AUTOSAR XML (schema 4-2-2)
package /STELLANTIS/EPT/ASWCs
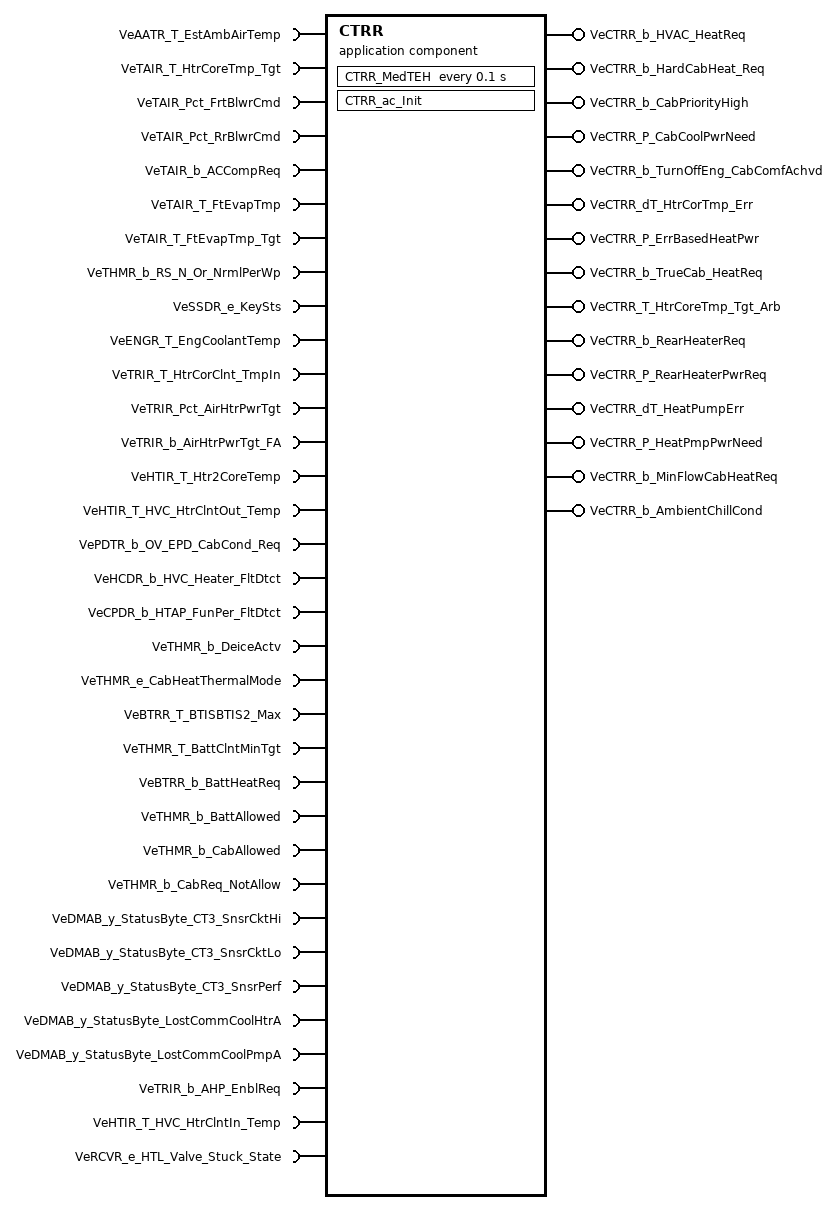
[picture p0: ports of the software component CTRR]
  application sw component type CTRR
    34 x require port:
      VeAATR_T_EstAmbAirTemp: variation-point={short-label=vpVeAATR_T_EstAmbAirTemp, sw-syscond=1}, nonqueued-receiver-com-spec{data-element=Value, init-value=0}, required-interface=VeAATR_T_EstAmbAirTemp
      VeTAIR_T_HtrCoreTmp_Tgt: variation-point={short-label=vpVeTAIR_T_HtrCoreTmp_Tgt, sw-syscond=1}, nonqueued-receiver-com-spec{data-element=Value, init-value=0}, required-interface=VeTAIR_T_HtrCoreTmp_Tgt
      VeTAIR_Pct_FrtBlwrCmd: variation-point={short-label=vpVeTAIR_Pct_FrtBlwrCmd, sw-syscond=1}, nonqueued-receiver-com-spec{data-element=Value, init-value=0}, required-interface=VeTAIR_Pct_FrtBlwrCmd
      VeTAIR_Pct_RrBlwrCmd: variation-point={short-label=vpVeTAIR_Pct_RrBlwrCmd, sw-syscond=1}, nonqueued-receiver-com-spec{data-element=Value, init-value=0}, required-interface=VeTAIR_Pct_RrBlwrCmd
      VeTAIR_b_ACCompReq: variation-point={short-label=vpVeTAIR_b_ACCompReq, sw-syscond=1}, nonqueued-receiver-com-spec{data-element=Value, init-value=0}, required-interface=VeTAIR_b_ACCompReq
      VeTAIR_T_FtEvapTmp: variation-point={short-label=vpVeTAIR_T_FtEvapTmp, sw-syscond=1}, nonqueued-receiver-com-spec{data-element=Value, init-value=0}, required-interface=VeTAIR_T_FtEvapTmp
      VeTAIR_T_FtEvapTmp_Tgt: variation-point={short-label=vpVeTAIR_T_FtEvapTmp_Tgt, sw-syscond=1}, nonqueued-receiver-com-spec{data-element=Value, init-value=0}, required-interface=VeTAIR_T_FtEvapTmp_Tgt
      VeTHMR_b_RS_N_Or_NrmlPerWp: variation-point={short-label=vpVeTHMR_b_RS_N_Or_NrmlPerWp, sw-syscond=1}, nonqueued-receiver-com-spec{data-element=Value, init-value=0}, required-interface=VeTHMR_b_RS_N_Or_NrmlPerWp
      VeSSDR_e_KeySts: variation-point={short-label=vpVeSSDR_e_KeySts, sw-syscond=1}, nonqueued-receiver-com-spec{data-element=Value, init-value=CeSSDR_e_KeyOff}, required-interface=VeSSDR_e_KeySts
      VeENGR_T_EngCoolantTemp: variation-point={short-label=vpVeENGR_T_EngCoolantTemp, sw-syscond=1}, nonqueued-receiver-com-spec{data-element=Value, init-value=0}, required-interface=VeENGR_T_EngCoolantTemp
      VeTRIR_T_HtrCorClnt_TmpIn: variation-point={short-label=vpVeTRIR_T_HtrCorClnt_TmpIn, sw-syscond=1}, nonqueued-receiver-com-spec{data-element=Value, init-value=0}, required-interface=VeTRIR_T_HtrCorClnt_TmpIn
      VeTRIR_Pct_AirHtrPwrTgt: variation-point={short-label=vpVeTRIR_Pct_AirHtrPwrTgt, sw-syscond=1}, nonqueued-receiver-com-spec{data-element=Value, init-value=0}, required-interface=VeTRIR_Pct_AirHtrPwrTgt
      VeTRIR_b_AirHtrPwrTgt_FA: variation-point={short-label=vpVeTRIR_b_AirHtrPwrTgt_FA, sw-syscond=1}, nonqueued-receiver-com-spec{data-element=Value, init-value=0}, required-interface=VeTRIR_b_AirHtrPwrTgt_FA
      VeHTIR_T_Htr2CoreTemp: variation-point={short-label=vpVeHTIR_T_Htr2CoreTemp, sw-syscond=1}, nonqueued-receiver-com-spec{data-element=Value, init-value=0}, required-interface=VeHTIR_T_Htr2CoreTemp
      VeHTIR_T_HVC_HtrClntOut_Temp: variation-point={short-label=vpVeHTIR_T_HVC_HtrClntOut_Temp, sw-syscond=1}, nonqueued-receiver-com-spec{data-element=Value, init-value=0}, required-interface=VeHTIR_T_HVC_HtrClntOut_Temp
      VePDTR_b_OV_EPD_CabCond_Req: variation-point={short-label=vpVePDTR_b_OV_EPD_CabCond_Req, sw-syscond=1}, nonqueued-receiver-com-spec{data-element=Value, init-value=0}, required-interface=VePDTR_b_OV_EPD_CabCond_Req
      VeHCDR_b_HVC_Heater_FltDtct: variation-point={short-label=vpVeHCDR_b_HVC_Heater_FltDtct, sw-syscond=1}, nonqueued-receiver-com-spec{data-element=Value, init-value=0}, required-interface=VeHCDR_b_HVC_Heater_FltDtct
      VeCPDR_b_HTAP_FunPer_FltDtct: variation-point={short-label=vpVeCPDR_b_HTAP_FunPer_FltDtct, sw-syscond=1}, nonqueued-receiver-com-spec{data-element=Value, init-value=0}, required-interface=VeCPDR_b_HTAP_FunPer_FltDtct
      VeTHMR_b_DeiceActv: variation-point={short-label=vpVeTHMR_b_DeiceActv, sw-syscond=1}, nonqueued-receiver-com-spec{data-element=Value, init-value=0}, required-interface=VeTHMR_b_DeiceActv
      VeTHMR_e_CabHeatThermalMode: variation-point={short-label=vpVeTHMR_e_CabHeatThermalMode, sw-syscond=1}, nonqueued-receiver-com-spec{data-element=Value, init-value=CeTHMR_e_NoActvHeat}, required-interface=VeTHMR_e_CabHeatThermalMode
      VeBTRR_T_BTISBTIS2_Max: variation-point={short-label=vpVeBTRR_T_BTISBTIS2_Max, sw-syscond=1}, nonqueued-receiver-com-spec{data-element=Value, init-value=0}, required-interface=VeBTRR_T_BTISBTIS2_Max
      VeTHMR_T_BattClntMinTgt: variation-point={short-label=vpVeTHMR_T_BattClntMinTgt, sw-syscond=1}, nonqueued-receiver-com-spec{data-element=Value, init-value=0}, required-interface=VeTHMR_T_BattClntMinTgt
      VeBTRR_b_BattHeatReq: variation-point={short-label=vpVeBTRR_b_BattHeatReq, sw-syscond=1}, nonqueued-receiver-com-spec{data-element=Value, init-value=0}, required-interface=VeBTRR_b_BattHeatReq
      VeTHMR_b_BattAllowed: variation-point={short-label=vpVeTHMR_b_BattAllowed, sw-syscond=1}, nonqueued-receiver-com-spec{data-element=Value, init-value=0}, required-interface=VeTHMR_b_BattAllowed
      VeTHMR_b_CabAllowed: variation-point={short-label=vpVeTHMR_b_CabAllowed, sw-syscond=1}, nonqueued-receiver-com-spec{data-element=Value, init-value=0}, required-interface=VeTHMR_b_CabAllowed
      VeTHMR_b_CabReq_NotAllow: variation-point={short-label=vpVeTHMR_b_CabReq_NotAllow, sw-syscond=1}, nonqueued-receiver-com-spec{data-element=Value, init-value=0}, required-interface=VeTHMR_b_CabReq_NotAllow
      VeDMAB_y_StatusByte_CT3_SnsrCktHi: variation-point={short-label=vpVeDMAB_y_StatusByte_CT3_SnsrCktHi, sw-syscond=1}, nonqueued-receiver-com-spec{data-element=Value, init-value=0}, required-interface=VeDMAB_y_StatusByte_CT3_SnsrCktHi
      VeDMAB_y_StatusByte_CT3_SnsrCktLo: variation-point={short-label=vpVeDMAB_y_StatusByte_CT3_SnsrCktLo, sw-syscond=1}, nonqueued-receiver-com-spec{data-element=Value, init-value=0}, required-interface=VeDMAB_y_StatusByte_CT3_SnsrCktLo
      VeDMAB_y_StatusByte_CT3_SnsrPerf: variation-point={short-label=vpVeDMAB_y_StatusByte_CT3_SnsrPerf, sw-syscond=1}, nonqueued-receiver-com-spec{data-element=Value, init-value=0}, required-interface=VeDMAB_y_StatusByte_CT3_SnsrPerf
      VeDMAB_y_StatusByte_LostCommCoolHtrA: variation-point={short-label=vpVeDMAB_y_StatusByte_LostCommCoolHtrA, sw-syscond=1}, nonqueued-receiver-com-spec{data-element=Value, init-value=0}, required-interface=VeDMAB_y_StatusByte_LostCommCoolHtrA
      VeDMAB_y_StatusByte_LostCommCoolPmpA: variation-point={short-label=vpVeDMAB_y_StatusByte_LostCommCoolPmpA, sw-syscond=1}, nonqueued-receiver-com-spec{data-element=Value, init-value=0}, required-interface=VeDMAB_y_StatusByte_LostCommCoolPmpA
      VeTRIR_b_AHP_EnblReq: variation-point={short-label=vpVeTRIR_b_AHP_EnblReq, sw-syscond=1}, nonqueued-receiver-com-spec{data-element=Value, init-value=0}, required-interface=VeTRIR_b_AHP_EnblReq
      VeHTIR_T_HVC_HtrClntIn_Temp: variation-point={short-label=vpVeHTIR_T_HVC_HtrClntIn_Temp, sw-syscond=1}, nonqueued-receiver-com-spec{data-element=Value, init-value=0}, required-interface=VeHTIR_T_HVC_HtrClntIn_Temp
      VeRCVR_e_HTL_Valve_Stuck_State: variation-point={short-label=vpVeRCVR_e_HTL_Valve_Stuck_State, sw-syscond=1}, nonqueued-receiver-com-spec{data-element=Value, init-value=CeRCVR_e_Closed}, required-interface=VeRCVR_e_HTL_Valve_Stuck_State
    15 x provide port, all with nonqueued-sender-com-spec{data-element=Value, init-value=0}:
      VeCTRR_b_HVAC_HeatReq: variation-point={short-label=vpVeCTRR_b_HVAC_HeatReq, sw-syscond=1}, provided-interface=VeCTRR_b_HVAC_HeatReq
      VeCTRR_b_HardCabHeat_Req: variation-point={short-label=vpVeCTRR_b_HardCabHeat_Req, sw-syscond=1}, provided-interface=VeCTRR_b_HardCabHeat_Req
      VeCTRR_b_CabPriorityHigh: variation-point={short-label=vpVeCTRR_b_CabPriorityHigh, sw-syscond=1}, provided-interface=VeCTRR_b_CabPriorityHigh
      VeCTRR_P_CabCoolPwrNeed: variation-point={short-label=vpVeCTRR_P_CabCoolPwrNeed, sw-syscond=1}, provided-interface=VeCTRR_P_CabCoolPwrNeed
      VeCTRR_b_TurnOffEng_CabComfAchvd: variation-point={short-label=vpVeCTRR_b_TurnOffEng_CabComfAchvd, sw-syscond=1}, provided-interface=VeCTRR_b_TurnOffEng_CabComfAchvd
      VeCTRR_dT_HtrCorTmp_Err: variation-point={short-label=vpVeCTRR_dT_HtrCorTmp_Err, sw-syscond=1}, provided-interface=VeCTRR_dT_HtrCorTmp_Err
      VeCTRR_P_ErrBasedHeatPwr: variation-point={short-label=vpVeCTRR_P_ErrBasedHeatPwr, sw-syscond=1}, provided-interface=VeCTRR_P_ErrBasedHeatPwr
      VeCTRR_b_TrueCab_HeatReq: variation-point={short-label=vpVeCTRR_b_TrueCab_HeatReq, sw-syscond=1}, provided-interface=VeCTRR_b_TrueCab_HeatReq
      VeCTRR_T_HtrCoreTmp_Tgt_Arb: variation-point={short-label=vpVeCTRR_T_HtrCoreTmp_Tgt_Arb, sw-syscond=1}, provided-interface=VeCTRR_T_HtrCoreTmp_Tgt_Arb
      VeCTRR_b_RearHeaterReq: variation-point={short-label=vpVeCTRR_b_RearHeaterReq, sw-syscond=1}, provided-interface=VeCTRR_b_RearHeaterReq
      VeCTRR_P_RearHeaterPwrReq: variation-point={short-label=vpVeCTRR_P_RearHeaterPwrReq, sw-syscond=1}, provided-interface=VeCTRR_P_RearHeaterPwrReq
      VeCTRR_dT_HeatPumpErr: variation-point={short-label=vpVeCTRR_dT_HeatPumpErr, sw-syscond=1}, provided-interface=VeCTRR_dT_HeatPumpErr
      VeCTRR_P_HeatPmpPwrNeed: variation-point={short-label=vpVeCTRR_P_HeatPmpPwrNeed, sw-syscond=1}, provided-interface=VeCTRR_P_HeatPmpPwrNeed
      VeCTRR_b_MinFlowCabHeatReq: variation-point={short-label=vpVeCTRR_b_MinFlowCabHeatReq, sw-syscond=1}, provided-interface=VeCTRR_b_MinFlowCabHeatReq
      VeCTRR_b_AmbientChillCond: variation-point={short-label=vpVeCTRR_b_AmbientChillCond, sw-syscond=1}, provided-interface=VeCTRR_b_AmbientChillCond
    behavior IB_CTRR: data-type-mapping=msADTtoIDTMapping, handle-termination-and-restart=NO-SUPPORT
      timing event Event_MedTEH: start-on-event=CTRR_MedTEH, period=0.1
      init event Event_CTRR_ac_Init: start-on-event=CTRR_ac_Init
      runnable CTRR_ac_Init
      runnable CTRR_MedTEH: variation-point={short-label=vpCTRR_MedTEH, sw-syscond=1}
        data-receive-point-by-arguments:
          34 x access:
            IN_VeAATR_T_EstAmbAirTemp_Value: accessed-variable=VeAATR_T_EstAmbAirTemp.Value, variation-point={short-label=vpIN_VeAATR_T_EstAmbAirTemp_Value, sw-syscond=1}
            IN_VeBTRR_T_BTISBTIS2_Max_Value: accessed-variable=VeBTRR_T_BTISBTIS2_Max.Value, variation-point={short-label=vpIN_VeBTRR_T_BTISBTIS2_Max_Value, sw-syscond=1}
            IN_VeBTRR_b_BattHeatReq_Value: accessed-variable=VeBTRR_b_BattHeatReq.Value, variation-point={short-label=vpIN_VeBTRR_b_BattHeatReq_Value, sw-syscond=1}
            IN_VeCPDR_b_HTAP_FunPer_FltDtct_Value: accessed-variable=VeCPDR_b_HTAP_FunPer_FltDtct.Value, variation-point={short-label=vpIN_VeCPDR_b_HTAP_FunPer_FltDtct_Value, sw-syscond=1}
            IN_VeDMAB_y_StatusByte_CT3_SnsrCktHi_Value: accessed-variable=VeDMAB_y_StatusByte_CT3_SnsrCktHi.Value, variation-point={short-label=vpIN_VeDMAB_y_StatusByte_CT3_SnsrCktHi_Value, sw-syscond=1}
            IN_VeDMAB_y_StatusByte_CT3_SnsrCktLo_Value: accessed-variable=VeDMAB_y_StatusByte_CT3_SnsrCktLo.Value, variation-point={short-label=vpIN_VeDMAB_y_StatusByte_CT3_SnsrCktLo_Value, sw-syscond=1}
            IN_VeDMAB_y_StatusByte_CT3_SnsrPerf_Value: accessed-variable=VeDMAB_y_StatusByte_CT3_SnsrPerf.Value, variation-point={short-label=vpIN_VeDMAB_y_StatusByte_CT3_SnsrPerf_Value, sw-syscond=1}
            IN_VeDMAB_y_StatusByte_LostCommCoolHtrA_Value: accessed-variable=VeDMAB_y_StatusByte_LostCommCoolHtrA.Value, variation-point={short-label=vpIN_VeDMAB_y_StatusByte_LostCommCoolHtrA_Value, sw-syscond=1}
            IN_VeDMAB_y_StatusByte_LostCommCoolPmpA_Value: accessed-variable=VeDMAB_y_StatusByte_LostCommCoolPmpA.Value, variation-point={short-label=vpIN_VeDMAB_y_StatusByte_LostCommCoolPmpA_Value, sw-syscond=1}
            IN_VeENGR_T_EngCoolantTemp_Value: accessed-variable=VeENGR_T_EngCoolantTemp.Value, variation-point={short-label=vpIN_VeENGR_T_EngCoolantTemp_Value, sw-syscond=1}
            IN_VeHCDR_b_HVC_Heater_FltDtct_Value: accessed-variable=VeHCDR_b_HVC_Heater_FltDtct.Value, variation-point={short-label=vpIN_VeHCDR_b_HVC_Heater_FltDtct_Value, sw-syscond=1}
            IN_VeHTIR_T_HVC_HtrClntIn_Temp_Value: accessed-variable=VeHTIR_T_HVC_HtrClntIn_Temp.Value, variation-point={short-label=vpIN_VeHTIR_T_HVC_HtrClntIn_Temp_Value, sw-syscond=1}
            IN_VeHTIR_T_HVC_HtrClntOut_Temp_Value: accessed-variable=VeHTIR_T_HVC_HtrClntOut_Temp.Value, variation-point={short-label=vpIN_VeHTIR_T_HVC_HtrClntOut_Temp_Value, sw-syscond=1}
            IN_VeHTIR_T_Htr2CoreTemp_Value: accessed-variable=VeHTIR_T_Htr2CoreTemp.Value, variation-point={short-label=vpIN_VeHTIR_T_Htr2CoreTemp_Value, sw-syscond=1}
            IN_VePDTR_b_OV_EPD_CabCond_Req_Value: accessed-variable=VePDTR_b_OV_EPD_CabCond_Req.Value, variation-point={short-label=vpIN_VePDTR_b_OV_EPD_CabCond_Req_Value, sw-syscond=1}
            IN_VeRCVR_e_HTL_Valve_Stuck_State_Value: accessed-variable=VeRCVR_e_HTL_Valve_Stuck_State.Value, variation-point={short-label=vpIN_VeRCVR_e_HTL_Valve_Stuck_State_Value, sw-syscond=1}
            IN_VeSSDR_e_KeySts_Value: accessed-variable=VeSSDR_e_KeySts.Value, variation-point={short-label=vpIN_VeSSDR_e_KeySts_Value, sw-syscond=1}
            IN_VeTAIR_Pct_FrtBlwrCmd_Value: accessed-variable=VeTAIR_Pct_FrtBlwrCmd.Value, variation-point={short-label=vpIN_VeTAIR_Pct_FrtBlwrCmd_Value, sw-syscond=1}
            IN_VeTAIR_Pct_RrBlwrCmd_Value: accessed-variable=VeTAIR_Pct_RrBlwrCmd.Value, variation-point={short-label=vpIN_VeTAIR_Pct_RrBlwrCmd_Value, sw-syscond=1}
            IN_VeTAIR_T_FtEvapTmp_Value: accessed-variable=VeTAIR_T_FtEvapTmp.Value, variation-point={short-label=vpIN_VeTAIR_T_FtEvapTmp_Value, sw-syscond=1}
            IN_VeTAIR_T_FtEvapTmp_Tgt_Value: accessed-variable=VeTAIR_T_FtEvapTmp_Tgt.Value, variation-point={short-label=vpIN_VeTAIR_T_FtEvapTmp_Tgt_Value, sw-syscond=1}
            IN_VeTAIR_T_HtrCoreTmp_Tgt_Value: accessed-variable=VeTAIR_T_HtrCoreTmp_Tgt.Value, variation-point={short-label=vpIN_VeTAIR_T_HtrCoreTmp_Tgt_Value, sw-syscond=1}
            IN_VeTAIR_b_ACCompReq_Value: accessed-variable=VeTAIR_b_ACCompReq.Value, variation-point={short-label=vpIN_VeTAIR_b_ACCompReq_Value, sw-syscond=1}
            IN_VeTHMR_T_BattClntMinTgt_Value: accessed-variable=VeTHMR_T_BattClntMinTgt.Value, variation-point={short-label=vpIN_VeTHMR_T_BattClntMinTgt_Value, sw-syscond=1}
            IN_VeTHMR_b_BattAllowed_Value: accessed-variable=VeTHMR_b_BattAllowed.Value, variation-point={short-label=vpIN_VeTHMR_b_BattAllowed_Value, sw-syscond=1}
            IN_VeTHMR_b_CabAllowed_Value: accessed-variable=VeTHMR_b_CabAllowed.Value, variation-point={short-label=vpIN_VeTHMR_b_CabAllowed_Value, sw-syscond=1}
            IN_VeTHMR_b_CabReq_NotAllow_Value: accessed-variable=VeTHMR_b_CabReq_NotAllow.Value, variation-point={short-label=vpIN_VeTHMR_b_CabReq_NotAllow_Value, sw-syscond=1}
            IN_VeTHMR_b_DeiceActv_Value: accessed-variable=VeTHMR_b_DeiceActv.Value, variation-point={short-label=vpIN_VeTHMR_b_DeiceActv_Value, sw-syscond=1}
            IN_VeTHMR_b_RS_N_Or_NrmlPerWp_Value: accessed-variable=VeTHMR_b_RS_N_Or_NrmlPerWp.Value, variation-point={short-label=vpIN_VeTHMR_b_RS_N_Or_NrmlPerWp_Value, sw-syscond=1}
            IN_VeTHMR_e_CabHeatThermalMode_Value: accessed-variable=VeTHMR_e_CabHeatThermalMode.Value, variation-point={short-label=vpIN_VeTHMR_e_CabHeatThermalMode_Value, sw-syscond=1}
            IN_VeTRIR_Pct_AirHtrPwrTgt_Value: accessed-variable=VeTRIR_Pct_AirHtrPwrTgt.Value, variation-point={short-label=vpIN_VeTRIR_Pct_AirHtrPwrTgt_Value, sw-syscond=1}
            IN_VeTRIR_T_HtrCorClnt_TmpIn_Value: accessed-variable=VeTRIR_T_HtrCorClnt_TmpIn.Value, variation-point={short-label=vpIN_VeTRIR_T_HtrCorClnt_TmpIn_Value, sw-syscond=1}
            IN_VeTRIR_b_AHP_EnblReq_Value: accessed-variable=VeTRIR_b_AHP_EnblReq.Value, variation-point={short-label=vpIN_VeTRIR_b_AHP_EnblReq_Value, sw-syscond=1}
            IN_VeTRIR_b_AirHtrPwrTgt_FA_Value: accessed-variable=VeTRIR_b_AirHtrPwrTgt_FA.Value, variation-point={short-label=vpIN_VeTRIR_b_AirHtrPwrTgt_FA_Value, sw-syscond=1}
        data-send-points:
          15 x access:
            OUT_VeCTRR_b_HVAC_HeatReq_Value: accessed-variable=VeCTRR_b_HVAC_HeatReq.Value, variation-point={short-label=vpOUT_VeCTRR_b_HVAC_HeatReq_Value, sw-syscond=1}
            OUT_VeCTRR_b_HardCabHeat_Req_Value: accessed-variable=VeCTRR_b_HardCabHeat_Req.Value, variation-point={short-label=vpOUT_VeCTRR_b_HardCabHeat_Req_Value, sw-syscond=1}
            OUT_VeCTRR_b_RearHeaterReq_Value: accessed-variable=VeCTRR_b_RearHeaterReq.Value, variation-point={short-label=vpOUT_VeCTRR_b_RearHeaterReq_Value, sw-syscond=1}
            OUT_VeCTRR_P_RearHeaterPwrReq_Value: accessed-variable=VeCTRR_P_RearHeaterPwrReq.Value, variation-point={short-label=vpOUT_VeCTRR_P_RearHeaterPwrReq_Value, sw-syscond=1}
            OUT_VeCTRR_dT_HeatPumpErr_Value: accessed-variable=VeCTRR_dT_HeatPumpErr.Value, variation-point={short-label=vpOUT_VeCTRR_dT_HeatPumpErr_Value, sw-syscond=1}
            OUT_VeCTRR_P_HeatPmpPwrNeed_Value: accessed-variable=VeCTRR_P_HeatPmpPwrNeed.Value, variation-point={short-label=vpOUT_VeCTRR_P_HeatPmpPwrNeed_Value, sw-syscond=1}
            OUT_VeCTRR_b_MinFlowCabHeatReq_Value: accessed-variable=VeCTRR_b_MinFlowCabHeatReq.Value, variation-point={short-label=vpOUT_VeCTRR_b_MinFlowCabHeatReq_Value, sw-syscond=1}
            OUT_VeCTRR_b_CabPriorityHigh_Value: accessed-variable=VeCTRR_b_CabPriorityHigh.Value, variation-point={short-label=vpOUT_VeCTRR_b_CabPriorityHigh_Value, sw-syscond=1}
            OUT_VeCTRR_b_AmbientChillCond_Value: accessed-variable=VeCTRR_b_AmbientChillCond.Value, variation-point={short-label=vpOUT_VeCTRR_b_AmbientChillCond_Value, sw-syscond=1}
            OUT_VeCTRR_P_CabCoolPwrNeed_Value: accessed-variable=VeCTRR_P_CabCoolPwrNeed.Value, variation-point={short-label=vpOUT_VeCTRR_P_CabCoolPwrNeed_Value, sw-syscond=1}
            OUT_VeCTRR_b_TurnOffEng_CabComfAchvd_Value: accessed-variable=VeCTRR_b_TurnOffEng_CabComfAchvd.Value, variation-point={short-label=vpOUT_VeCTRR_b_TurnOffEng_CabComfAchvd_Value, sw-syscond=1}
            OUT_VeCTRR_dT_HtrCorTmp_Err_Value: accessed-variable=VeCTRR_dT_HtrCorTmp_Err.Value, variation-point={short-label=vpOUT_VeCTRR_dT_HtrCorTmp_Err_Value, sw-syscond=1}
            OUT_VeCTRR_P_ErrBasedHeatPwr_Value: accessed-variable=VeCTRR_P_ErrBasedHeatPwr.Value, variation-point={short-label=vpOUT_VeCTRR_P_ErrBasedHeatPwr_Value, sw-syscond=1}
            OUT_VeCTRR_b_TrueCab_HeatReq_Value: accessed-variable=VeCTRR_b_TrueCab_HeatReq.Value, variation-point={short-label=vpOUT_VeCTRR_b_TrueCab_HeatReq_Value, sw-syscond=1}
            OUT_VeCTRR_T_HtrCoreTmp_Tgt_Arb_Value: accessed-variable=VeCTRR_T_HtrCoreTmp_Tgt_Arb.Value, variation-point={short-label=vpOUT_VeCTRR_T_HtrCoreTmp_Tgt_Arb_Value, sw-syscond=1}
      4 x variation point proxy, all with category=CONDITION:
        Variant_CTRR_1: condition-access=1
        Variant_CTRR_3: condition-access=1
        Variant_CTRR_4: condition-access=0
        Variant_CTRR_5: condition-access=0
